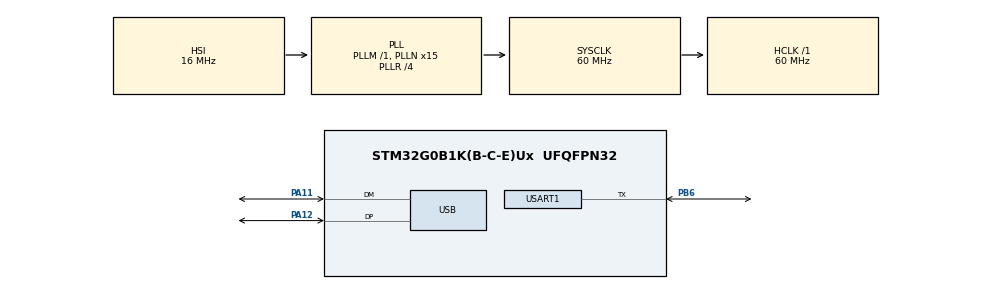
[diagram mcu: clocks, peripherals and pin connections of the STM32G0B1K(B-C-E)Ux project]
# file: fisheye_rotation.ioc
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Mcu.Family=STM32G0
Mcu.Name=STM32G0B1K(B-C-E)Ux
Mcu.Package=UFQFPN32
NVIC.USART1_IRQn=true\:1\:0\:true\:false\:true\:true\:true\:true
NVIC.USB_UCPD1_2_IRQn=true\:0\:0\:false\:false\:true\:true\:true\:true
PA11\ [PA9].Mode=Device
PA11\ [PA9].Signal=USB_DM
PA12\ [PA10].Mode=Device
PA12\ [PA10].Signal=USB_DP
PA13.Mode=Serial_Wire
PA13.Signal=SYS_SWDIO
PA14-BOOT0.Mode=Serial_Wire
PA14-BOOT0.Signal=SYS_SWCLK
PB6.GPIO_PuPdOD=GPIO_NOPULL
PB6.GPIO_Speed=GPIO_SPEED_FREQ_VERY_HIGH
PB6.Mode=Half_duplex(single_wire_mode)
PB6.Signal=USART1_TX
ProjectManager.HeapSize=0x200
ProjectManager.StackSize=0x400
ProjectManager.TargetToolchain=Makefile
RCC.ADCFreq_Value=60000000
RCC.AHBFreq_Value=60000000
RCC.CortexFreq_Value=60000000
RCC.EXTERNAL_CLOCK_VALUE=48000
RCC.FDCANCLockSelection=RCC_FDCANCLKSOURCE_PLL
RCC.HCLKFreq_Value=60000000
RCC.HSE_VALUE=8000000
RCC.HSI48_VALUE=48000000
RCC.HSI_VALUE=16000000
RCC.LSE_VALUE=32768
RCC.PLLN=15
RCC.PLLR=RCC_PLLR_DIV4
RCC.SYSCLKFreq_VALUE=60000000
RCC.SYSCLKSource=RCC_SYSCLKSOURCE_PLLCLK
RCC.USBFreq_Value=48000000
RCC.VCOOutputFreq_Value=240000000
TIM1.Period=255
TIM1.Prescaler=479
USART1.BaudRate=1000000
USART1.OverrunDisableParam=ADVFEATURE_OVERRUN_DISABLE
USART1.VirtualMode-Half_duplex(single_wire_mode)=VM_ASYNC
USB_DEVICE.CLASS_NAME_FS=CDC
USB_DEVICE.VirtualMode=Cdc
USB_DEVICE.VirtualModeFS=Cdc_FS
VP_SYS_VS_DBSignals.Mode=DisableDeadBatterySignals
VP_TIM1_VS_ClockSourceINT.Mode=Internal
VP_USB_DEVICE_VS_USB_DEVICE_CDC_FS.Mode=CDC_FS
board=custom

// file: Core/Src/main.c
/* USER CODE BEGIN Header */
/**
 ******************************************************************************
 * @file           : main.c
 * @brief          : Main program body
 ******************************************************************************
 * @attention
 *
 * Copyright (c) 2026 STMicroelectronics.
 * All rights reserved.
 *
 * This software is licensed under terms that can be found in the LICENSE file
 * in the root directory of this software component.
 * If no LICENSE file comes with this software, it is provided AS-IS.
 *
 ******************************************************************************
 */
/* USER CODE END Header */
#include "main.h"
#include "usb_device.h"

/* USER CODE BEGIN Includes */
#include "servo.h"
#include <stdio.h>
#include <string.h>
/* USER CODE END Includes */

TIM_HandleTypeDef htim1;

UART_HandleTypeDef huart1;

void SystemClock_Config(void);
static void MX_GPIO_Init(void);
static void MX_TIM1_Init(void);
static void MX_USART1_UART_Init(void);

/* USER CODE BEGIN 0 */

// Position offset
static uint16_t position_offset = 0;

// External USB device handle and buffers
extern uint8_t UserRxBufferFS[2048];
extern USBD_HandleTypeDef hUsbDeviceFS;
extern uint8_t CDC_Transmit_FS(uint8_t *Buf, uint16_t Len);

/* USER CODE END 0 */

int main(void)
{

    /* MCU
     * Configuration--------------------------------------------------------*/

    /* Reset of all peripherals, Initializes the Flash interface and the
     * Systick.
     */
    HAL_Init();

    /* Configure the system clock */
    SystemClock_Config();

    /* Initialize all configured peripherals */
    MX_GPIO_Init();
    MX_TIM1_Init();
    MX_USART1_UART_Init();
    MX_USB_Device_Init();
    /* USER CODE BEGIN 2 */

    // Initialize servo
    servo_init(1); // Servo ID = 1

    HAL_Delay(100);

    // Read current position and use it as zero reference
    uint16_t startup_pos = 0;
    servo_status_t status;
    while (1)
    {
        status = servo_read_position(&startup_pos);
        if (status == SERVO_OK)
        {
            position_offset = startup_pos;
            break;
        }
        HAL_Delay(100); // Retry every 100ms
    }

    /* USER CODE END 2 */

    /* Infinite loop */
    while (1)
    {

    }
}

void SystemClock_Config(void)
{
    RCC_OscInitTypeDef RCC_OscInitStruct = {0};
    RCC_ClkInitTypeDef RCC_ClkInitStruct = {0};

    /** Configure the main internal regulator output voltage
     */
    HAL_PWREx_ControlVoltageScaling(PWR_REGULATOR_VOLTAGE_SCALE1);

    /** Initializes the RCC Oscillators according to the specified parameters
     * in the RCC_OscInitTypeDef structure.
     */
    RCC_OscInitStruct.OscillatorType = RCC_OSCILLATORTYPE_HSI | RCC_OSCILLATORTYPE_HSI48;
    RCC_OscInitStruct.HSIState = RCC_HSI_ON;
    RCC_OscInitStruct.HSI48State = RCC_HSI48_ON;
    RCC_OscInitStruct.HSIDiv = RCC_HSI_DIV1;
    RCC_OscInitStruct.HSICalibrationValue = RCC_HSICALIBRATION_DEFAULT;
    RCC_OscInitStruct.PLL.PLLState = RCC_PLL_ON;
    RCC_OscInitStruct.PLL.PLLSource = RCC_PLLSOURCE_HSI;
    RCC_OscInitStruct.PLL.PLLM = RCC_PLLM_DIV1;
    RCC_OscInitStruct.PLL.PLLN = 15;
    RCC_OscInitStruct.PLL.PLLP = RCC_PLLP_DIV2;
    RCC_OscInitStruct.PLL.PLLQ = RCC_PLLQ_DIV2;
    RCC_OscInitStruct.PLL.PLLR = RCC_PLLR_DIV4;
    if (HAL_RCC_OscConfig(&RCC_OscInitStruct) != HAL_OK)
    {
        Error_Handler();
    }

    /** Initializes the CPU, AHB and APB buses clocks
     */
    RCC_ClkInitStruct.ClockType = RCC_CLOCKTYPE_HCLK | RCC_CLOCKTYPE_SYSCLK | RCC_CLOCKTYPE_PCLK1;
    RCC_ClkInitStruct.SYSCLKSource = RCC_SYSCLKSOURCE_PLLCLK;
    RCC_ClkInitStruct.AHBCLKDivider = RCC_SYSCLK_DIV1;
    RCC_ClkInitStruct.APB1CLKDivider = RCC_HCLK_DIV1;

    if (HAL_RCC_ClockConfig(&RCC_ClkInitStruct, FLASH_LATENCY_2) != HAL_OK)
    {
        Error_Handler();
    }
}

static void MX_TIM1_Init(void)
{

    TIM_ClockConfigTypeDef sClockSourceConfig = {0};
    TIM_MasterConfigTypeDef sMasterConfig = {0};

    htim1.Instance = TIM1;
    htim1.Init.Prescaler = 479;
    htim1.Init.CounterMode = TIM_COUNTERMODE_UP;
    htim1.Init.Period = 255;
    htim1.Init.ClockDivision = TIM_CLOCKDIVISION_DIV1;
    htim1.Init.RepetitionCounter = 0;
    htim1.Init.AutoReloadPreload = TIM_AUTORELOAD_PRELOAD_DISABLE;
    if (HAL_TIM_Base_Init(&htim1) != HAL_OK)
    {
        Error_Handler();
    }
    sClockSourceConfig.ClockSource = TIM_CLOCKSOURCE_INTERNAL;
    if (HAL_TIM_ConfigClockSource(&htim1, &sClockSourceConfig) != HAL_OK)
    {
        Error_Handler();
    }
    sMasterConfig.MasterOutputTrigger = TIM_TRGO_RESET;
    sMasterConfig.MasterOutputTrigger2 = TIM_TRGO2_RESET;
    sMasterConfig.MasterSlaveMode = TIM_MASTERSLAVEMODE_DISABLE;
    if (HAL_TIMEx_MasterConfigSynchronization(&htim1, &sMasterConfig) != HAL_OK)
    {
        Error_Handler();
    }
}

static void MX_USART1_UART_Init(void)
{

    huart1.Instance = USART1;
    huart1.Init.BaudRate = 1000000;
    huart1.Init.WordLength = UART_WORDLENGTH_8B;
    huart1.Init.StopBits = UART_STOPBITS_1;
    huart1.Init.Parity = UART_PARITY_NONE;
    huart1.Init.Mode = UART_MODE_TX_RX;
    huart1.Init.HwFlowCtl = UART_HWCONTROL_NONE;
    huart1.Init.OverSampling = UART_OVERSAMPLING_16;
    huart1.Init.OneBitSampling = UART_ONE_BIT_SAMPLE_DISABLE;
    huart1.Init.ClockPrescaler = UART_PRESCALER_DIV1;
    huart1.AdvancedInit.AdvFeatureInit = UART_ADVFEATURE_RXOVERRUNDISABLE_INIT;
    huart1.AdvancedInit.OverrunDisable = UART_ADVFEATURE_OVERRUN_DISABLE;
    if (HAL_HalfDuplex_Init(&huart1) != HAL_OK)
    {
        Error_Handler();
    }
    if (HAL_UARTEx_SetTxFifoThreshold(&huart1, UART_TXFIFO_THRESHOLD_1_8) != HAL_OK)
    {
        Error_Handler();
    }
    if (HAL_UARTEx_SetRxFifoThreshold(&huart1, UART_RXFIFO_THRESHOLD_1_8) != HAL_OK)
    {
        Error_Handler();
    }
    if (HAL_UARTEx_DisableFifoMode(&huart1) != HAL_OK)
    {
        Error_Handler();
    }
}

static void MX_GPIO_Init(void)
{

    /* GPIO Ports Clock Enable */
    __HAL_RCC_GPIOA_CLK_ENABLE();
    __HAL_RCC_GPIOB_CLK_ENABLE();

}

/* USER CODE BEGIN 4 */

// Binary protocol commands
#define CMD_SET_POSITION 0x01
#define CMD_READ_POSITION 0x02

void process_degree_command(uint8_t *cmd, uint16_t len)
{
    if (len == 0)
    {
        return;
    }

    uint8_t response[8];
    uint16_t response_len = 0;

    switch (cmd[0])
    {
    case CMD_SET_POSITION:
        // Format: [0x01] [POS_HIGH] [POS_LOW] (3 bytes)
        if (len >= 3)
        {
            uint16_t position = (cmd[1] << 8) | cmd[2];

            // Apply offset (relative to startup position)
            uint32_t actual_position_wide = (uint32_t)position + (uint32_t)position_offset;

            // Clamp to servo range (0-1023)
            if (actual_position_wide > 1023)
            {
                actual_position_wide = 1023;
            }
            uint16_t actual_position = (uint16_t)actual_position_wide;

            // Reverse rotation direction
            actual_position = 1023 - actual_position;

            servo_status_t status = servo_set_position(actual_position, 200, 0);

            // Response: [STATUS] (1 byte)
            response[0] = (uint8_t)status;
            response_len = 1;
        }
        break;

    case CMD_READ_POSITION:
        // Format: [0x02] (1 byte)
        {
            uint16_t pos = 0;
            servo_status_t status = servo_read_position(&pos);

            // Remove offset to get position relative to startup
            int32_t relative_pos = (int32_t)pos - (int32_t)position_offset;
            if (relative_pos < 0)
            {
                relative_pos = 0;
            }
            if (relative_pos > 1023)
            {
                relative_pos = 1023;
            }

            // Response: [STATUS] [POS_HIGH] [POS_LOW] (3 bytes)
            response[0] = (uint8_t)status;
            response[1] = (relative_pos >> 8) & 0xFF;
            response[2] = relative_pos & 0xFF;
            response_len = 3;
        }
        break;

    default:
        // Unknown command, respond with error status (1 byte)
        response[0] = 0xFF;
        response_len = 1;
        break;
    }

    if (response_len > 0)
    {
        CDC_Transmit_FS(response, response_len);
    }
}

/* USER CODE END 4 */

void Error_Handler(void)
{
    /* USER CODE BEGIN Error_Handler_Debug */
    /* User can add his own implementation to report the HAL error return state
     */
    __disable_irq();
    while (1)
    {
    }
    /* USER CODE END Error_Handler_Debug */
}
#ifdef USE_FULL_ASSERT
/**
 * @brief  Reports the name of the source file and the source line number
 *         where the assert_param error has occurred.
 * @param  file: pointer to the source file name
 * @param  line: assert_param error line source number
 * @retval None
 */
void assert_failed(uint8_t *file, uint32_t line)
{
    /* USER CODE BEGIN 6 */
    /* User can add his own implementation to report the file name and line
       number, ex: printf("Wrong parameters value: file %s on line %d\r\n",
       file, line) */
    /* USER CODE END 6 */
}
#endif /* USE_FULL_ASSERT */
